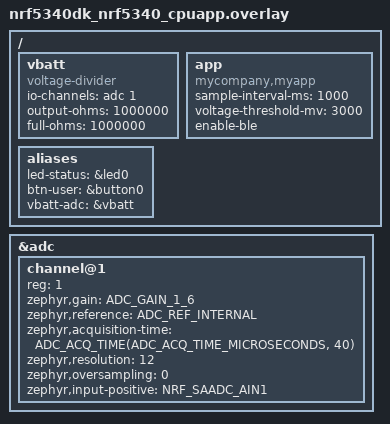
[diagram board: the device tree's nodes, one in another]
/* nrf5340dk_nrf5340_cpuapp.overlay */

/ {
    vbatt: vbatt {
        compatible = "voltage-divider";
        io-channels = <&adc 1>;
        output-ohms = <1000000>;
        full-ohms = <1000000>;
    };

    app {
        compatible = "mycompany,myapp";
        sample-interval-ms = <1000>;
        voltage-threshold-mv = <3000>;
        enable-ble;
    };

    aliases {
        led-status = &led0;
        btn-user = &button0;
        vbatt-adc = &vbatt;
    };
};

&adc {
    #address-cells = <1>;
    #size-cells = <0>;
    status = "okay";

    channel@1 {
        reg = <1>;
        zephyr,gain = "ADC_GAIN_1_6";
        zephyr,reference = "ADC_REF_INTERNAL";
        zephyr,acquisition-time = <ADC_ACQ_TIME(ADC_ACQ_TIME_MICROSECONDS, 40)>;
        zephyr,resolution = <12>;
        zephyr,oversampling = <0>;
        zephyr,input-positive = <NRF_SAADC_AIN1>;
    };
};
